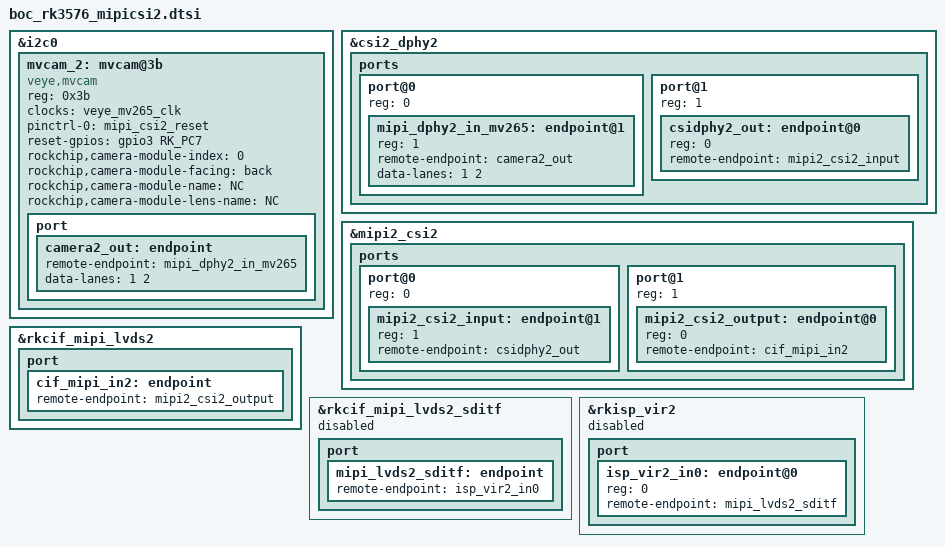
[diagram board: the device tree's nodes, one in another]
&i2c0 {
        mvcam_2: mvcam@3b{
               compatible = "veye,mvcam";
               reg = <0x3b>;
               clocks = <&veye_mv265_clk>;
               clock-names = "xvclk";
	       pinctrl-names = "default";
	       pinctrl-0 = <&mipi_csi2_reset>;
	       reset-gpios = <&gpio3 RK_PC7 GPIO_ACTIVE_HIGH>;
        //        reset-gpios = <&xl9555 10 GPIO_ACTIVE_HIGH>;

               rockchip,camera-module-index = <0>;
               rockchip,camera-module-facing = "back";
               rockchip,camera-module-name = "NC";
               rockchip,camera-module-lens-name = "NC";
               port {
                        camera2_out: endpoint {
                               remote-endpoint = <&mipi_dphy2_in_mv265>;
                               data-lanes = <1 2>;
                       };
               };
       };

};

&csi2_dphy2 {
	status = "okay";

        ports {
                #address-cells = <1>;
                #size-cells = <0>;
                port@0 {
                        reg = <0>;
			#address-cells = <1>;
                        #size-cells = <0>;

                        mipi_dphy2_in_mv265: endpoint@1 {
                                reg = <1>;
                                remote-endpoint = <&camera2_out>;
                                data-lanes = <1 2>;
                        };
                };
                port@1 {
                        reg = <1>;
                        #address-cells = <1>;
                        #size-cells = <0>;

                        csidphy2_out: endpoint@0 {
                                reg = <0>;
                                remote-endpoint = <&mipi2_csi2_input>;
                        };
                };
        };
};

&mipi2_csi2 {
        status = "okay";

        ports {
                #address-cells = <1>;
                #size-cells = <0>;

                port@0 {
                        reg = <0>;
                        #address-cells = <1>;
                        #size-cells = <0>;

                        mipi2_csi2_input: endpoint@1 {
                                reg = <1>;
                                remote-endpoint = <&csidphy2_out>;
                        };
                };

                port@1 {
                        reg = <1>;
                        #address-cells = <1>;
                        #size-cells = <0>;

                        mipi2_csi2_output: endpoint@0 {
                                reg = <0>;
                                remote-endpoint = <&cif_mipi_in2>;
                        };
                };
        };
};

&rkcif_mipi_lvds2 {
        status = "okay";

        port {
                cif_mipi_in2: endpoint {
                        remote-endpoint = <&mipi2_csi2_output>;
                };
        };
};

&rkcif_mipi_lvds2_sditf {
	status = "disabled";

	port {
                mipi_lvds2_sditf: endpoint {
                        remote-endpoint = <&isp_vir2_in0>;
                };
        };
};

&rkisp_vir2 {
        status = "disabled";

        port {
                #address-cells = <1>;
                #size-cells = <0>;

                isp_vir2_in0: endpoint@0 {
                        reg = <0>;
                        remote-endpoint = <&mipi_lvds2_sditf>;
                };
        };
};
